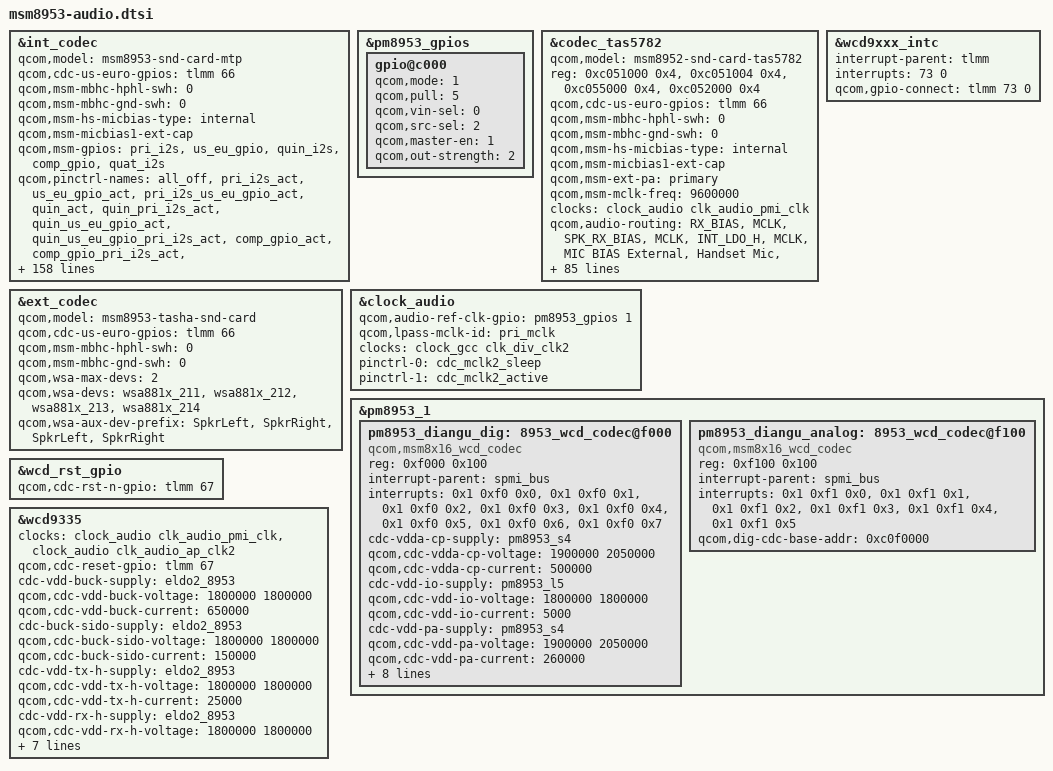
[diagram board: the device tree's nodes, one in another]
/*
 * Copyright (c) 2015-2016, The Linux Foundation. All rights reserved.
 *
 * This program is free software; you can redistribute it and/or modify
 * it under the terms of the GNU General Public License version 2 and
 * only version 2 as published by the Free Software Foundation.
 *
 * This program is distributed in the hope that it will be useful,
 * but WITHOUT ANY WARRANTY; without even the implied warranty of
 * MERCHANTABILITY or FITNESS FOR A PARTICULAR PURPOSE.  See the
 * GNU General Public License for more details.
 */

#include "msm8953-wsa881x.dtsi"

&int_codec {
	qcom,model = "msm8953-snd-card-mtp";

	qcom,cdc-us-euro-gpios = <&tlmm 66 0>;
	qcom,msm-mbhc-hphl-swh = <0>;
	qcom,msm-mbhc-gnd-swh = <0>;
	qcom,msm-hs-micbias-type = "internal";
	qcom,msm-micbias1-ext-cap;

	qcom,msm-gpios =
		"pri_i2s",
		"us_eu_gpio",
		"quin_i2s",
		"comp_gpio",
		"quat_i2s";
	qcom,pinctrl-names =
		"all_off",
		"pri_i2s_act",
		"us_eu_gpio_act",
		"pri_i2s_us_eu_gpio_act",
		"quin_act",
		"quin_pri_i2s_act",
		"quin_us_eu_gpio_act",
		"quin_us_eu_gpio_pri_i2s_act",
		"comp_gpio_act",
		"comp_gpio_pri_i2s_act",
		"comp_gpio_us_eu_gpio_act",
		"comp_gpio_pri_i2s_us_eu_gpio_act",
		"comp_gpio_quin_act",
		"comp_gpio_quin_pri_i2s_act",
		"comp_gpio_quin_us_eu_gpio_act",
		"comp_gpio_quin_us_eu_gpio_pri_i2s_act",
		"quat_i2s_act",
		"quat_i2s_act_pri_i2s_act",
		"quat_i2s_act_us_eu_gpio_act",
		"quat_i2s_act_pri_i2s_act_us_eu_gpio_act",
		"quat_i2s_act_quin_i2s_act",
		"quat_i2s_act_quin_i2s_act_pri_i2s_act",
		"quat_i2s_act_quin_i2s_act_us_eu_gpio_act",
		"quat_i2s_act_quin_i2s_act_us_eu_gpio_act_pri_i2s_act",
		"quat_i2s_act_comp_gpio_act",
		"quat_i2s_act_comp_gpio_act_pri_i2s_act",
		"quat_i2s_act_comp_gpio_act_us_eu_gpio_act",
		"quat_i2s_act_comp_gpio_act_pri_i2s_act_us_eu_gpio_act",
		"quat_i2s_act_comp_gpio_act_quin_i2s_act",
		"quat_i2s_act_comp_gpio_act_quin_i2s_act_pri_i2s_act",
		"quat_i2s_act_comp_gpio_act_quin_i2s_act_us_eu_gpio_act",
		"quat_i2s_act_comp_gpio_act_quin_i2s_act_pri_i2s_act_us_eu_gpio_act";
	pinctrl-names =
		"all_off",
		"pri_i2s_act",
		"us_eu_gpio_act",
		"pri_i2s_us_eu_gpio_act",
		"quin_act",
		"quin_pri_i2s_act",
		"quin_us_eu_gpio_act",
		"quin_us_eu_gpio_pri_i2s_act",
		"comp_gpio_act",
		"comp_gpio_pri_i2s_act",
		"comp_gpio_us_eu_gpio_act",
		"comp_gpio_pri_i2s_us_eu_gpio_act",
		"comp_gpio_quin_act",
		"comp_gpio_quin_pri_i2s_act",
		"comp_gpio_quin_us_eu_gpio_act",
		"comp_gpio_quin_us_eu_gpio_pri_i2s_act",
		"quat_i2s_act",
		"quat_i2s_act_pri_i2s_act",
		"quat_i2s_act_us_eu_gpio_act",
		"quat_i2s_act_pri_i2s_act_us_eu_gpio_act",
		"quat_i2s_act_quin_i2s_act",
		"quat_i2s_act_quin_i2s_act_pri_i2s_act",
		"quat_i2s_act_quin_i2s_act_us_eu_gpio_act",
		"quat_i2s_act_quin_i2s_act_us_eu_gpio_act_pri_i2s_act",
		"quat_i2s_act_comp_gpio_act",
		"quat_i2s_act_comp_gpio_act_pri_i2s_act",
		"quat_i2s_act_comp_gpio_act_us_eu_gpio_act",
		"quat_i2s_act_comp_gpio_act_pri_i2s_act_us_eu_gpio_act",
		"quat_i2s_act_comp_gpio_act_quin_i2s_act",
		"quat_i2s_act_comp_gpio_act_quin_i2s_act_pri_i2s_act",
		"quat_i2s_act_comp_gpio_act_quin_i2s_act_us_eu_gpio_act",
		"quat_i2s_act_comp_gpio_act_quin_i2s_act_pri_i2s_act_us_eu_gpio_act";

 	pinctrl-0 = <&cdc_pdm_lines_sus &cdc_pdm_comp_lines_sus
 		&cdc_pdm_lines_2_sus &cross_conn_det_sus
		&pri_tlmm_lines_sus &pri_tlmm_ws_sus &sec_tlmm_lines_sus>;
 	pinctrl-1 = <&cdc_pdm_lines_act &cdc_pdm_comp_lines_sus
 		&cdc_pdm_lines_2_act &cross_conn_det_sus
		&pri_tlmm_lines_sus &pri_tlmm_ws_sus &sec_tlmm_lines_sus>;
 	pinctrl-2 = <&cdc_pdm_lines_sus &cdc_pdm_comp_lines_sus
 		&cdc_pdm_lines_2_sus &cross_conn_det_act
		&pri_tlmm_lines_sus &pri_tlmm_ws_sus &sec_tlmm_lines_sus>;
 	pinctrl-3 = <&cdc_pdm_lines_act &cdc_pdm_comp_lines_sus
 		&cdc_pdm_lines_2_act &cross_conn_det_act
		&pri_tlmm_lines_sus &pri_tlmm_ws_sus &sec_tlmm_lines_sus>;
 	pinctrl-4 = <&cdc_pdm_lines_sus &cdc_pdm_comp_lines_sus
 		&cdc_pdm_lines_2_sus &cross_conn_det_sus
		&pri_tlmm_lines_act &pri_tlmm_ws_act &sec_tlmm_lines_sus>;
 	pinctrl-5 = <&cdc_pdm_lines_act &cdc_pdm_comp_lines_sus
 		&cdc_pdm_lines_2_act &cross_conn_det_sus
		&pri_tlmm_lines_act &pri_tlmm_ws_act &sec_tlmm_lines_sus>;
 	pinctrl-6 = <&cdc_pdm_lines_sus &cdc_pdm_comp_lines_sus
 		&cdc_pdm_lines_2_sus &cross_conn_det_act
		&pri_tlmm_lines_act &pri_tlmm_ws_act &sec_tlmm_lines_sus>;
 	pinctrl-7 = <&cdc_pdm_lines_act &cdc_pdm_comp_lines_sus
 		&cdc_pdm_lines_2_act &cross_conn_det_act
		&pri_tlmm_lines_act &pri_tlmm_ws_act &sec_tlmm_lines_sus>;
 	pinctrl-8 = <&cdc_pdm_lines_sus &cdc_pdm_comp_lines_act
 		&cdc_pdm_lines_2_sus &cross_conn_det_sus
		&pri_tlmm_lines_sus &pri_tlmm_ws_sus &sec_tlmm_lines_sus>;
 	pinctrl-9 = <&cdc_pdm_lines_act &cdc_pdm_comp_lines_act
 		&cdc_pdm_lines_2_act &cross_conn_det_sus
		&pri_tlmm_lines_sus &pri_tlmm_ws_sus &sec_tlmm_lines_sus>;
 	pinctrl-10 = <&cdc_pdm_lines_sus &cdc_pdm_comp_lines_act
 		&cdc_pdm_lines_2_sus &cross_conn_det_act
		&pri_tlmm_lines_sus &pri_tlmm_ws_sus &sec_tlmm_lines_sus>;
 	pinctrl-11 = <&cdc_pdm_lines_act &cdc_pdm_comp_lines_act
 		&cdc_pdm_lines_2_act &cross_conn_det_act
		&pri_tlmm_lines_sus &pri_tlmm_ws_sus &sec_tlmm_lines_sus>;
 	pinctrl-12 = <&cdc_pdm_lines_sus &cdc_pdm_comp_lines_act
 		&cdc_pdm_lines_2_sus &cross_conn_det_sus
		&pri_tlmm_lines_act &pri_tlmm_ws_act &sec_tlmm_lines_sus>;
 	pinctrl-13 = <&cdc_pdm_lines_act &cdc_pdm_comp_lines_act
 		&cdc_pdm_lines_2_act &cross_conn_det_sus
		&pri_tlmm_lines_act &pri_tlmm_ws_act &sec_tlmm_lines_sus>;
 	pinctrl-14 = <&cdc_pdm_lines_sus &cdc_pdm_comp_lines_act
 		&cdc_pdm_lines_2_sus &cross_conn_det_act
		&pri_tlmm_lines_act &pri_tlmm_ws_act &sec_tlmm_lines_sus>;
 	pinctrl-15 = <&cdc_pdm_lines_act &cdc_pdm_comp_lines_act
 		&cdc_pdm_lines_2_act &cross_conn_det_act
		&pri_tlmm_lines_act &pri_tlmm_ws_act &sec_tlmm_lines_sus>;
	pinctrl-16 = <&sec_tlmm_lines_act &cdc_pdm_lines_sus &cdc_pdm_lines_2_sus &cross_conn_det_sus &pri_tlmm_lines_sus &pri_tlmm_ws_sus &cdc_pdm_comp_lines_sus>;
	pinctrl-17 = <&sec_tlmm_lines_act &cdc_pdm_lines_act &cdc_pdm_lines_2_act &cross_conn_det_sus &pri_tlmm_lines_sus &pri_tlmm_ws_sus &cdc_pdm_comp_lines_sus>;
	pinctrl-18 = <&sec_tlmm_lines_act &cdc_pdm_lines_sus &cdc_pdm_lines_2_sus &cross_conn_det_act &pri_tlmm_lines_sus &pri_tlmm_ws_sus &cdc_pdm_comp_lines_sus>;
	pinctrl-19 = <&sec_tlmm_lines_act &cdc_pdm_lines_act &cdc_pdm_lines_2_act &cross_conn_det_act &pri_tlmm_lines_sus &pri_tlmm_ws_sus &cdc_pdm_comp_lines_sus>;
	pinctrl-20 = <&sec_tlmm_lines_act &cdc_pdm_lines_sus &cdc_pdm_lines_2_sus &cross_conn_det_sus &pri_tlmm_lines_act &pri_tlmm_ws_act &cdc_pdm_comp_lines_sus>;
	pinctrl-21 = <&sec_tlmm_lines_act &cdc_pdm_lines_act &cdc_pdm_lines_2_act &cross_conn_det_sus &pri_tlmm_lines_act &pri_tlmm_ws_act &cdc_pdm_comp_lines_sus>;
	pinctrl-22 = <&sec_tlmm_lines_act &cdc_pdm_lines_sus &cdc_pdm_lines_2_sus &cross_conn_det_act &pri_tlmm_lines_act &pri_tlmm_ws_act &cdc_pdm_comp_lines_sus>;
	pinctrl-23 = <&sec_tlmm_lines_act &cdc_pdm_lines_act &cdc_pdm_lines_2_act &cross_conn_det_act &pri_tlmm_lines_act &pri_tlmm_ws_act &cdc_pdm_comp_lines_sus>;
	pinctrl-24 = <&sec_tlmm_lines_act &cdc_pdm_lines_sus &cdc_pdm_lines_2_sus &cross_conn_det_sus &pri_tlmm_lines_sus &pri_tlmm_ws_sus &cdc_pdm_comp_lines_act>;
	pinctrl-25 = <&sec_tlmm_lines_act &cdc_pdm_lines_act &cdc_pdm_lines_2_act &cross_conn_det_sus &pri_tlmm_lines_sus &pri_tlmm_ws_sus &cdc_pdm_comp_lines_act>;
	pinctrl-26 = <&sec_tlmm_lines_act &cdc_pdm_lines_sus &cdc_pdm_lines_2_sus &cross_conn_det_act &pri_tlmm_lines_sus &pri_tlmm_ws_sus &cdc_pdm_comp_lines_act>;
	pinctrl-27 = <&sec_tlmm_lines_act &cdc_pdm_lines_act &cdc_pdm_lines_2_act &cross_conn_det_act &pri_tlmm_lines_sus &pri_tlmm_ws_sus &cdc_pdm_comp_lines_act>;
	pinctrl-28 = <&sec_tlmm_lines_act &cdc_pdm_lines_sus &cdc_pdm_lines_2_sus &cross_conn_det_sus &pri_tlmm_lines_act &pri_tlmm_ws_act &cdc_pdm_comp_lines_act>;
	pinctrl-29 = <&sec_tlmm_lines_act &cdc_pdm_lines_act &cdc_pdm_lines_2_act &cross_conn_det_sus &pri_tlmm_lines_act &pri_tlmm_ws_act &cdc_pdm_comp_lines_act>;
	pinctrl-30 = <&sec_tlmm_lines_act &cdc_pdm_lines_sus &cdc_pdm_lines_2_sus &cross_conn_det_act &pri_tlmm_lines_act &pri_tlmm_ws_act &cdc_pdm_comp_lines_act>;
	pinctrl-31 = <&sec_tlmm_lines_act &cdc_pdm_lines_act &cdc_pdm_lines_2_act &cross_conn_det_act &pri_tlmm_lines_act &pri_tlmm_ws_act &cdc_pdm_comp_lines_act>;
 

	asoc-codec = <&stub_codec>, <&pm8953_diangu_dig>, <&hdmi_dba>;
	asoc-codec-names = "msm-stub-codec.1", "cajon_codec",
						"msm-hdmi-dba-codec-rx";
	asoc-wsa-codec-names = "wsa881x-i2c-codec.2-000f";
	asoc-wsa-codec-prefixes = "SpkrMono";

	msm-vdd-wsa-switch-supply = <&pm8953_l5>;
	qcom,msm-vdd-wsa-switch-voltage = <1800000>;
	qcom,msm-vdd-wsa-switch-current = <10000>;
};

&pm8953_gpios {
	gpio@c000 {
		status = "ok";
		qcom,mode = <1>;
		qcom,pull = <5>;
		qcom,vin-sel = <0>;
		qcom,src-sel = <2>;
		qcom,master-en = <1>;
		qcom,out-strength = <2>;
	};
};

&codec_tas5782 {
	qcom,model = "msm8952-snd-card-tas5782";
	reg = <0xc051000 0x4>,
	      <0xc051004 0x4>,
	      <0xc055000 0x4>,
	      <0xc052000 0x4>;
  	reg-names = "csr_gp_io_mux_mic_ctl",
		    "csr_gp_io_mux_spkr_ctl",
		    "csr_gp_io_lpaif_pri_pcm_pri_mode_muxsel",
		    "csr_gp_io_mux_quin_ctl";
	qcom,cdc-us-euro-gpios = <&tlmm 66 0>;
	qcom,msm-mbhc-hphl-swh = <0>;
	qcom,msm-mbhc-gnd-swh = <0>;
	qcom,msm-hs-micbias-type = "internal";
	qcom,msm-micbias1-ext-cap;
	qcom,msm-ext-pa = "primary";
	qcom,msm-mclk-freq = <9600000>;
	qcom,msm-mbhc-hphl-swh = <0>;
	qcom,msm-mbhc-gnd-swh = <0>;

	clock-names = "wcd_clk";
	clocks = <&clock_audio clk_audio_pmi_clk>;
	/*
	qcom,audio-routing =
		"DAC", "MCLK",
        "DAC", "MCLK";
    */
	qcom,audio-routing =
		"RX_BIAS", "MCLK",
		"SPK_RX_BIAS", "MCLK",
		"INT_LDO_H", "MCLK",
		"MIC BIAS External", "Handset Mic",
		"MIC BIAS External2", "Headset Mic",
		"MIC BIAS External", "Secondary Mic",
		"AMIC1", "MIC BIAS External",
		"AMIC2", "MIC BIAS External2",
		"AMIC3", "MIC BIAS External",
		"WSA_SPK OUT", "VDD_WSA_SWITCH",
		"SpkrMono WSA_IN", "WSA_SPK OUT";
	
	/*qcom,hdmi-dba-codec-rx;*/

	qcom,msm-gpios = "pri_i2s", 
					"us_eu_gpio",
					"quin_i2s",
					"quat_i2s";
	qcom,pinctrl-names = "all_off", 
					"pri_i2s_act",
					"us_eu_gpio_act", 
					"pri_i2s_us_eu_gpio_act",
					"quin_act",
					"quin_pri_i2s_act",
					"quin_us_eu_gpio_act",
					"quin_us_eu_gpio_pri_i2s_act",
					"quat_i2s_act",
					"quat_pri_i2s_act",
					"quat_us_eu_gpio_act",
					"quat_pri_i2s_us_eu_gpio_act",
					"quat_quin_act",
					"quat_quin_pri_i2s_act",
					"quat_quin_us_eu_gpio_act",
					"quat_quin_us_eu_gpio_pri_i2s_act";
	pinctrl-names = "all_off",
					"pri_i2s_act",
					"us_eu_gpio_act",
					"pri_i2s_us_eu_gpio_act",
					"quin_act",
					"quin_pri_i2s_act",
					"quin_us_eu_gpio_act",
					"quin_us_eu_gpio_pri_i2s_act",
					"quat_i2s_act",
					"quat_pri_i2s_act",
					"quat_us_eu_gpio_act",
					"quat_pri_i2s_us_eu_gpio_act",
					"quat_quin_act",
					"quat_quin_pri_i2s_act",
					"quat_quin_us_eu_gpio_act",
					"quat_quin_us_eu_gpio_pri_i2s_act"; 
	pinctrl-0 = <&sec_tlmm_lines_sus &pri_tlmm_lines_sus &pri_tlmm_ws_sus>;		/* all_off */
	pinctrl-1 = <&sec_tlmm_lines_sus &pri_tlmm_lines_act &pri_tlmm_ws_act>;		/* pri_i2s_act */
	pinctrl-2 = <&sec_tlmm_lines_sus &pri_tlmm_lines_sus &pri_tlmm_ws_sus>;		/* us_eu_gpio_act */
	pinctrl-3 = <&sec_tlmm_lines_sus &pri_tlmm_lines_act &pri_tlmm_ws_act>;		/* pri_i2s_us_eu_gpio_act */
	pinctrl-4 = <&sec_tlmm_lines_sus &pri_tlmm_lines_act &pri_tlmm_ws_act>;		/* quin_act  */
	pinctrl-5 = <&sec_tlmm_lines_sus &pri_tlmm_lines_act &pri_tlmm_ws_act>;		/* quin_pri_i2s_act */
	pinctrl-6 = <&sec_tlmm_lines_sus &pri_tlmm_lines_act &pri_tlmm_ws_act>;		/* quin_us_eu_gpio_act */
	pinctrl-7 = <&sec_tlmm_lines_sus &pri_tlmm_lines_act &pri_tlmm_ws_act>;		/* quin_us_eu_gpio_pri_i2s_act */
	pinctrl-8 = <&sec_tlmm_lines_act &pri_tlmm_lines_sus &pri_tlmm_ws_sus>;		/* quat_i2s_act */
	pinctrl-9 = <&sec_tlmm_lines_act &pri_tlmm_lines_act &pri_tlmm_ws_act>;		/* quat_pri_i2s_act */
	pinctrl-10 = <&sec_tlmm_lines_act &pri_tlmm_lines_sus &pri_tlmm_ws_sus>;	/* quat_us_eu_gpio_act */
	pinctrl-11 = <&sec_tlmm_lines_act &pri_tlmm_lines_act &pri_tlmm_ws_act>;	/* quat_pri_i2s_us_eu_gpio_act */
	pinctrl-12 = <&sec_tlmm_lines_act &pri_tlmm_lines_act &pri_tlmm_ws_act>;	/* quat_quin_act */
	pinctrl-13 = <&sec_tlmm_lines_act &pri_tlmm_lines_act &pri_tlmm_ws_act>;	/* quat_quin_pri_i2s_act */
	pinctrl-14 = <&sec_tlmm_lines_act &pri_tlmm_lines_act &pri_tlmm_ws_act>;	/* quat_quin_us_eu_gpio_act */
	pinctrl-15 = <&sec_tlmm_lines_act &pri_tlmm_lines_act &pri_tlmm_ws_act>;	/* quat_quin_us_eu_gpio_pri_i2s_act */

	asoc-platform = <&pcm0>, <&pcm1>, <&pcm2>, <&voip>, <&voice>,
			<&loopback>, <&compress>, <&hostless>,
			<&afe>, <&lsm>, <&routing>, <&lpa>;
	asoc-platform-names = "msm-pcm-dsp.0", "msm-pcm-dsp.1",
			"msm-pcm-dsp.2", "msm-voip-dsp",
			"msm-pcm-voice", "msm-pcm-loopback",
			"msm-compress-dsp", "msm-pcm-hostless",
			"msm-pcm-afe", "msm-lsm-client",
			"msm-pcm-routing", "msm-pcm-lpa";
	asoc-cpu = <&dai_pri_auxpcm>,
			<&dai_mi2s0>, <&dai_mi2s1>,
			<&dai_mi2s2>, <&dai_mi2s3>,
			<&dai_mi2s5>, <&dai_mi2s6>,
			<&sb_0_rx>, <&sb_0_tx>, <&sb_1_rx>, <&sb_1_tx>,
			<&sb_3_rx>, <&sb_3_tx>, <&sb_4_rx>, <&sb_4_tx>,
			<&bt_sco_rx>, <&bt_sco_tx>,
			<&int_fm_rx>, <&int_fm_tx>,
			<&afe_pcm_rx>, <&afe_pcm_tx>,
			<&afe_proxy_rx>, <&afe_proxy_tx>,
			<&incall_record_rx>, <&incall_record_tx>,
			<&incall_music_rx>, <&incall_music_2_rx>;
	asoc-cpu-names = "msm-dai-q6-auxpcm.1",
			"msm-dai-q6-mi2s.0", "msm-dai-q6-mi2s.1",
			"msm-dai-q6-mi2s.2", "msm-dai-q6-mi2s.3",
			"msm-dai-q6-mi2s.5", "msm-dai-q6-mi2s.6",
			"msm-dai-q6-dev.16384", "msm-dai-q6-dev.16385",
			"msm-dai-q6-dev.16386", "msm-dai-q6-dev.16387",
			"msm-dai-q6-dev.16390", "msm-dai-q6-dev.16391",
			"msm-dai-q6-dev.16392", "msm-dai-q6-dev.16393",
			"msm-dai-q6-dev.12288", "msm-dai-q6-dev.12289",
			"msm-dai-q6-dev.12292", "msm-dai-q6-dev.12293",
			"msm-dai-q6-dev.224", "msm-dai-q6-dev.225",
			"msm-dai-q6-dev.241", "msm-dai-q6-dev.240",
			"msm-dai-q6-dev.32771", "msm-dai-q6-dev.32772",
			"msm-dai-q6-dev.32773", "msm-dai-q6-dev.32770";
	
	asoc-codec = <&stub_codec>, <&tas5782m>, <&cx2092x>;
	asoc-codec-names = "msm-stub-codec.1", "tas5782m.2-004a", "cx2092x.5-0041";
	/*
	asoc-codec = <&stub_codec>, <&pm8953_diangu_dig>, <&hdmi_dba>, <&tas5766>, <&cx2092x>, <&tas5782>;
	asoc-codec-names = "msm-stub-codec.1", "cajon_codec",
						"msm-hdmi-dba-codec-rx", "tas2559.3-004f", "cx2092x-codec.1";
	asoc-wsa-codec-names = "wsa881x-i2c-codec.2-000f";
	asoc-wsa-codec-prefixes = "SpkrMono";
	msm-vdd-wsa-switch-supply = <&pm8953_l5>;
	qcom,msm-vdd-wsa-switch-voltage = <1800000>;
	qcom,msm-vdd-wsa-switch-current = <10000>;
	*/
};

&ext_codec {
	qcom,model = "msm8953-tasha-snd-card";

	qcom,cdc-us-euro-gpios = <&tlmm 66 0>;
	qcom,msm-mbhc-hphl-swh = <0>;
	qcom,msm-mbhc-gnd-swh = <0>;

	qcom,wsa-max-devs = <2>;
	qcom,wsa-devs = <&wsa881x_211>, <&wsa881x_212>,
			<&wsa881x_213>, <&wsa881x_214>;
	qcom,wsa-aux-dev-prefix = "SpkrLeft", "SpkrRight",
				"SpkrLeft", "SpkrRight";
};

&wcd9xxx_intc {
	interrupt-parent = <&tlmm>;
	interrupts = <73 0>;
	qcom,gpio-connect = <&tlmm 73 0>;
};

&clock_audio {
	qcom,audio-ref-clk-gpio = <&pm8953_gpios 1 0>;
	qcom,lpass-mclk-id = "pri_mclk";
	clocks = <&clock_gcc clk_div_clk2>;
	pinctrl-names = "sleep", "active";
	pinctrl-0 = <&cdc_mclk2_sleep>;
	pinctrl-1 = <&cdc_mclk2_active>;
};

&pm8953_1 {
	pm8953_diangu_dig: 8953_wcd_codec@f000 {
		compatible = "qcom,msm8x16_wcd_codec";
		reg = <0xf000 0x100>;
		interrupt-parent = <&spmi_bus>;
		interrupts = <0x1 0xf0 0x0>,
			     <0x1 0xf0 0x1>,
			     <0x1 0xf0 0x2>,
			     <0x1 0xf0 0x3>,
			     <0x1 0xf0 0x4>,
			     <0x1 0xf0 0x5>,
			     <0x1 0xf0 0x6>,
			     <0x1 0xf0 0x7>;
		interrupt-names = "spk_cnp_int",
				  "spk_clip_int",
				  "spk_ocp_int",
				  "ins_rem_det1",
				  "but_rel_det",
				  "but_press_det",
				  "ins_rem_det",
				  "mbhc_int";

		cdc-vdda-cp-supply = <&pm8953_s4>;
		qcom,cdc-vdda-cp-voltage = <1900000 2050000>;
		qcom,cdc-vdda-cp-current = <500000>;

		cdc-vdd-io-supply = <&pm8953_l5>;
		qcom,cdc-vdd-io-voltage = <1800000 1800000>;
		qcom,cdc-vdd-io-current = <5000>;

		cdc-vdd-pa-supply = <&pm8953_s4>;
		qcom,cdc-vdd-pa-voltage = <1900000 2050000>;
		qcom,cdc-vdd-pa-current = <260000>;

		cdc-vdd-mic-bias-supply = <&pm8953_l13>;
		qcom,cdc-vdd-mic-bias-voltage = <3125000 3125000>;
		qcom,cdc-vdd-mic-bias-current = <5000>;

		qcom,cdc-mclk-clk-rate = <9600000>;

		qcom,cdc-static-supplies =  "cdc-vdd-io",
					   "cdc-vdd-pa",
					   "cdc-vdda-cp";

		qcom,cdc-on-demand-supplies = "cdc-vdd-mic-bias";
		qcom,dig-cdc-base-addr = <0xc0f0000>;
	};

	pm8953_diangu_analog: 8953_wcd_codec@f100 {
		compatible = "qcom,msm8x16_wcd_codec";
		reg = <0xf100 0x100>;
		interrupt-parent = <&spmi_bus>;
		interrupts = <0x1 0xf1 0x0>,
			     <0x1 0xf1 0x1>,
			     <0x1 0xf1 0x2>,
			     <0x1 0xf1 0x3>,
			     <0x1 0xf1 0x4>,
			     <0x1 0xf1 0x5>;
		interrupt-names = "ear_ocp_int",
				  "hphr_ocp_int",
				  "hphl_ocp_det",
				  "ear_cnp_int",
				  "hphr_cnp_int",
				  "hphl_cnp_int";
		qcom,dig-cdc-base-addr = <0xc0f0000>;
	};
};

&wcd_rst_gpio {
	qcom,cdc-rst-n-gpio = <&tlmm 67 0>;
};

&wcd9335 {
	clock-names = "wcd_clk", "wcd_native_clk";
	clocks = <&clock_audio clk_audio_pmi_clk>,
		<&clock_audio clk_audio_ap_clk2>;

	qcom,cdc-reset-gpio = <&tlmm 67 0>;

	cdc-vdd-buck-supply = <&eldo2_8953>;
	qcom,cdc-vdd-buck-voltage = <1800000 1800000>;
	qcom,cdc-vdd-buck-current = <650000>;

	cdc-buck-sido-supply = <&eldo2_8953>;
	qcom,cdc-buck-sido-voltage = <1800000 1800000>;
	qcom,cdc-buck-sido-current = <150000>;

	cdc-vdd-tx-h-supply = <&eldo2_8953>;
	qcom,cdc-vdd-tx-h-voltage = <1800000 1800000>;
	qcom,cdc-vdd-tx-h-current = <25000>;

	cdc-vdd-rx-h-supply = <&eldo2_8953>;
	qcom,cdc-vdd-rx-h-voltage = <1800000 1800000>;
	qcom,cdc-vdd-rx-h-current = <25000>;

	cdc-vdd-px-supply = <&eldo2_8953>;
	qcom,cdc-vdd-px-voltage = <1800000 1800000>;
	qcom,cdc-vdd-px-current = <10000>;

	cdc-vdd-mic-bias-supply = <&pm8953_l13>;
	qcom,cdc-vdd-mic-bias-voltage = <3125000 3125000>;
	qcom,cdc-vdd-mic-bias-current = <15000>;
};
